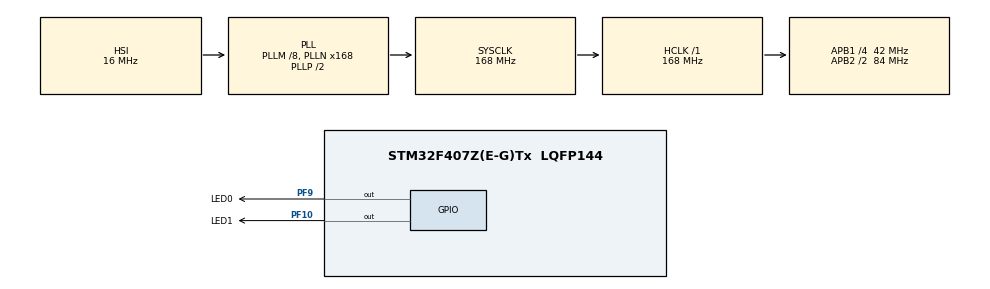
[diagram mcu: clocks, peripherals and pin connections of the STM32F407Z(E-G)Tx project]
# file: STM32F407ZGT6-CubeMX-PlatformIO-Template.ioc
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FREERTOS.Tasks01=LED0A,24,128,StartLED0A,Default,NULL,Dynamic,NULL,NULL;LED0B,8,128,StartLED0B,Default,NULL,Dynamic,NULL,NULL;LED1A,24,128,StartLED1A,Default,NULL,Dynamic,NULL,NULL;LED1B,8,128,StartLED1B,Default,NULL,Dynamic,NULL,NULL
FREERTOS.configUSE_NEWLIB_REENTRANT=0
Mcu.Family=STM32F4
Mcu.Name=STM32F407Z(E-G)Tx
Mcu.Package=LQFP144
NVIC.PriorityGroup=NVIC_PRIORITYGROUP_4
NVIC.TIM8_TRG_COM_TIM14_IRQn=true\:15\:0\:false\:false\:true\:false\:false\:true\:true
NVIC.TimeBase=TIM8_TRG_COM_TIM14_IRQn
NVIC.TimeBaseIP=TIM14
PA13.Mode=Serial_Wire
PA13.Signal=SYS_JTMS-SWDIO
PA14.Mode=Serial_Wire
PA14.Signal=SYS_JTCK-SWCLK
PC14-OSC32_IN.Mode=LSE-External-Oscillator
PC14-OSC32_IN.Signal=RCC_OSC32_IN
PC15-OSC32_OUT.Mode=LSE-External-Oscillator
PC15-OSC32_OUT.Signal=RCC_OSC32_OUT
PF10.GPIO_Label=LED1
PF10.Signal=GPIO_Output
PF9.GPIO_Label=LED0
PF9.Signal=GPIO_Output
PH0-OSC_IN.Mode=HSE-External-Oscillator
PH0-OSC_IN.Signal=RCC_OSC_IN
PH1-OSC_OUT.Mode=HSE-External-Oscillator
PH1-OSC_OUT.Signal=RCC_OSC_OUT
ProjectManager.HeapSize=0x200
ProjectManager.StackSize=0x400
ProjectManager.TargetToolchain=STM32CubeIDE
RCC.48MHZClocksFreq_Value=84000000
RCC.AHBFreq_Value=168000000
RCC.APB1CLKDivider=RCC_HCLK_DIV4
RCC.APB1Freq_Value=42000000
RCC.APB1TimFreq_Value=84000000
RCC.APB2CLKDivider=RCC_HCLK_DIV2
RCC.APB2Freq_Value=84000000
RCC.APB2TimFreq_Value=168000000
RCC.CortexFreq_Value=168000000
RCC.HCLKFreq_Value=168000000
RCC.HSE_VALUE=25000000
RCC.HSI_VALUE=16000000
RCC.PLLM=8
RCC.PLLN=168
RCC.SYSCLKFreq_VALUE=168000000
RCC.SYSCLKSource=RCC_SYSCLKSOURCE_PLLCLK
RCC.VCOOutputFreq_Value=336000000
VP_FREERTOS_VS_CMSIS_V2.Mode=CMSIS_V2
VP_SYS_VS_tim14.Mode=TIM14
board=custom

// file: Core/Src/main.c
/* USER CODE BEGIN Header */
/**
  ******************************************************************************
  * @file           : main.c
  * @brief          : Main program body
  ******************************************************************************
  * @attention
  *
  * Copyright (c) 2022 STMicroelectronics.
  * All rights reserved.
  *
  * This software is licensed under terms that can be found in the LICENSE file
  * in the root directory of this software component.
  * If no LICENSE file comes with this software, it is provided AS-IS.
  *
  ******************************************************************************
  */
/* USER CODE END Header */
#include "main.h"
#include "cmsis_os.h"
#include "gpio.h"

void SystemClock_Config(void);
void MX_FREERTOS_Init(void);

int main(void)
{

  /* MCU Configuration--------------------------------------------------------*/

  /* Reset of all peripherals, Initializes the Flash interface and the Systick. */
  HAL_Init();

  /* Configure the system clock */
  SystemClock_Config();

  /* Initialize all configured peripherals */
  MX_GPIO_Init();

  /* Init scheduler */
  osKernelInitialize();  /* Call init function for freertos objects (in freertos.c) */
  MX_FREERTOS_Init();

  /* Start scheduler */
  osKernelStart();

  /* We should never get here as control is now taken by the scheduler */
  /* Infinite loop */
  while (1)
  {

  }
}

void SystemClock_Config(void)
{
  RCC_OscInitTypeDef RCC_OscInitStruct = {0};
  RCC_ClkInitTypeDef RCC_ClkInitStruct = {0};

  /** Configure the main internal regulator output voltage
  */
  __HAL_RCC_PWR_CLK_ENABLE();
  __HAL_PWR_VOLTAGESCALING_CONFIG(PWR_REGULATOR_VOLTAGE_SCALE1);

  /** Initializes the RCC Oscillators according to the specified parameters
  * in the RCC_OscInitTypeDef structure.
  */
  RCC_OscInitStruct.OscillatorType = RCC_OSCILLATORTYPE_HSI;
  RCC_OscInitStruct.HSIState = RCC_HSI_ON;
  RCC_OscInitStruct.HSICalibrationValue = RCC_HSICALIBRATION_DEFAULT;
  RCC_OscInitStruct.PLL.PLLState = RCC_PLL_ON;
  RCC_OscInitStruct.PLL.PLLSource = RCC_PLLSOURCE_HSI;
  RCC_OscInitStruct.PLL.PLLM = 8;
  RCC_OscInitStruct.PLL.PLLN = 168;
  RCC_OscInitStruct.PLL.PLLP = RCC_PLLP_DIV2;
  RCC_OscInitStruct.PLL.PLLQ = 4;
  if (HAL_RCC_OscConfig(&RCC_OscInitStruct) != HAL_OK)
  {
    Error_Handler();
  }

  /** Initializes the CPU, AHB and APB buses clocks
  */
  RCC_ClkInitStruct.ClockType = RCC_CLOCKTYPE_HCLK|RCC_CLOCKTYPE_SYSCLK
                              |RCC_CLOCKTYPE_PCLK1|RCC_CLOCKTYPE_PCLK2;
  RCC_ClkInitStruct.SYSCLKSource = RCC_SYSCLKSOURCE_PLLCLK;
  RCC_ClkInitStruct.AHBCLKDivider = RCC_SYSCLK_DIV1;
  RCC_ClkInitStruct.APB1CLKDivider = RCC_HCLK_DIV4;
  RCC_ClkInitStruct.APB2CLKDivider = RCC_HCLK_DIV2;

  if (HAL_RCC_ClockConfig(&RCC_ClkInitStruct, FLASH_LATENCY_5) != HAL_OK)
  {
    Error_Handler();
  }
}

void HAL_TIM_PeriodElapsedCallback(TIM_HandleTypeDef *htim)
{
  if (htim->Instance == TIM14) {
    HAL_IncTick();
  }
}

void Error_Handler(void)
{
  __disable_irq();
  while (1)
  {
  }
}

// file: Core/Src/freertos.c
/* USER CODE BEGIN Header */
/**
  ******************************************************************************
  * File Name          : freertos.c
  * Description        : Code for freertos applications
  ******************************************************************************
  * @attention
  *
  * Copyright (c) 2022 STMicroelectronics.
  * All rights reserved.
  *
  * This software is licensed under terms that can be found in the LICENSE file
  * in the root directory of this software component.
  * If no LICENSE file comes with this software, it is provided AS-IS.
  *
  ******************************************************************************
  */
/* USER CODE END Header */

#include "FreeRTOS.h"
#include "task.h"
#include "main.h"
#include "cmsis_os.h"

/* Definitions for LED0A */
osThreadId_t LED0AHandle;
const osThreadAttr_t LED0A_attributes = {
  .name = "LED0A",
  .stack_size = 128 * 4,
  .priority = (osPriority_t) osPriorityNormal,
};
/* Definitions for LED0B */
osThreadId_t LED0BHandle;
const osThreadAttr_t LED0B_attributes = {
  .name = "LED0B",
  .stack_size = 128 * 4,
  .priority = (osPriority_t) osPriorityLow,
};
/* Definitions for LED1A */
osThreadId_t LED1AHandle;
const osThreadAttr_t LED1A_attributes = {
  .name = "LED1A",
  .stack_size = 128 * 4,
  .priority = (osPriority_t) osPriorityNormal,
};
/* Definitions for LED1B */
osThreadId_t LED1BHandle;
const osThreadAttr_t LED1B_attributes = {
  .name = "LED1B",
  .stack_size = 128 * 4,
  .priority = (osPriority_t) osPriorityLow,
};

void StartLED0A(void *argument);
void StartLED0B(void *argument);
void StartLED1A(void *argument);
void StartLED1B(void *argument);

void MX_FREERTOS_Init(void); /* (MISRA C 2004 rule 8.1) */

void MX_FREERTOS_Init(void) {

  /* Create the thread(s) */
  /* creation of LED0A */
  LED0AHandle = osThreadNew(StartLED0A, NULL, &LED0A_attributes);

  /* creation of LED0B */
  LED0BHandle = osThreadNew(StartLED0B, NULL, &LED0B_attributes);

  /* creation of LED1A */
  LED1AHandle = osThreadNew(StartLED1A, NULL, &LED1A_attributes);

  /* creation of LED1B */
  LED1BHandle = osThreadNew(StartLED1B, NULL, &LED1B_attributes);

}

void StartLED0A(void *argument)
{
  /* USER CODE BEGIN StartLED0A */
  /* Infinite loop */
  for(;;)
  {
    HAL_GPIO_TogglePin(LED0_GPIO_Port, LED0_Pin);
    osDelay(1000);
  }
  /* USER CODE END StartLED0A */
}

void StartLED0B(void *argument)
{
  /* USER CODE BEGIN StartLED0B */
  /* Infinite loop */
  for(;;)
  {
    HAL_GPIO_TogglePin(LED0_GPIO_Port, LED0_Pin);
    osDelay(1100);
  }
  /* USER CODE END StartLED0B */
}

void StartLED1A(void *argument)
{
  /* USER CODE BEGIN StartLED1A */
  /* Infinite loop */
  for(;;)
  {
    HAL_GPIO_TogglePin(LED1_GPIO_Port, LED1_Pin);
    osDelay(1000);
  }
  /* USER CODE END StartLED1A */
}

void StartLED1B(void *argument)
{
  /* USER CODE BEGIN StartLED1B */
  /* Infinite loop */
  for(;;)
  {
    HAL_GPIO_TogglePin(LED1_GPIO_Port, LED1_Pin);
    osDelay(1050);
  }
  /* USER CODE END StartLED1B */
}
